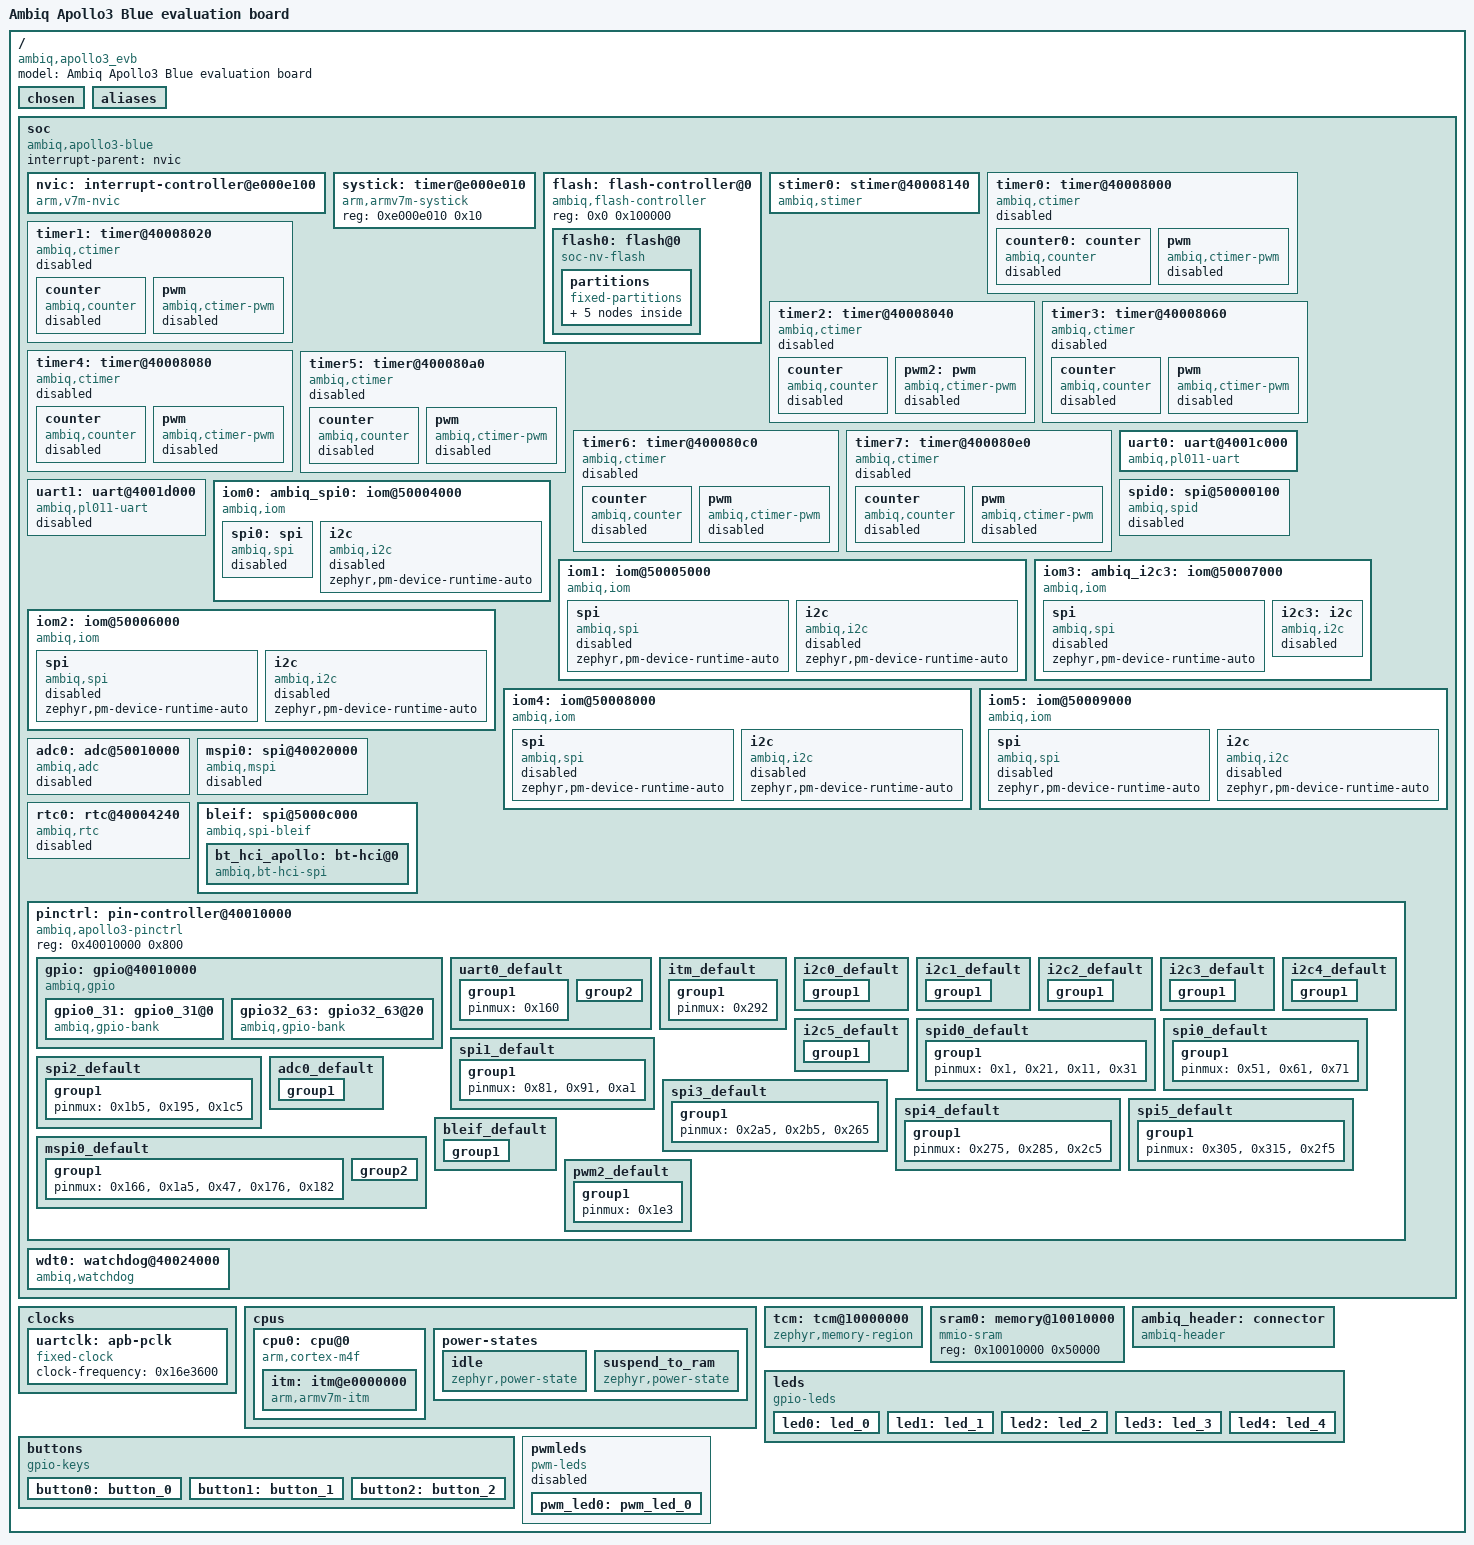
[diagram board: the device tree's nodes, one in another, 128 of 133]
/dts-v1/;

/* node '/' defined in zephyr/dts/common/skeleton.dtsi:9 */
/ {
	#address-cells = < 0x1 >;                      /* in zephyr/dts/common/skeleton.dtsi:10 */
	#size-cells = < 0x1 >;                         /* in zephyr/dts/common/skeleton.dtsi:11 */
	model = "Ambiq Apollo3 Blue evaluation board"; /* in zephyr/boards/ambiq/apollo3_evb/apollo3_evb.dts:8 */
	compatible = "ambiq,apollo3_evb";              /* in zephyr/boards/ambiq/apollo3_evb/apollo3_evb.dts:9 */

	/* node '/chosen' defined in zephyr/dts/common/skeleton.dtsi:13 */
	chosen {
		zephyr,itcm = &tcm;                       /* in zephyr/boards/ambiq/apollo3_evb/apollo3_evb.dts:12 */
		zephyr,sram = &sram0;                     /* in zephyr/boards/ambiq/apollo3_evb/apollo3_evb.dts:13 */
		zephyr,flash = &flash0;                   /* in zephyr/boards/ambiq/apollo3_evb/apollo3_evb.dts:14 */
		zephyr,console = &uart0;                  /* in zephyr/boards/ambiq/apollo3_evb/apollo3_evb.dts:15 */
		zephyr,shell-uart = &uart0;               /* in zephyr/boards/ambiq/apollo3_evb/apollo3_evb.dts:16 */
		zephyr,uart-mcumgr = &uart0;              /* in zephyr/boards/ambiq/apollo3_evb/apollo3_evb.dts:17 */
		zephyr,uart-pipe = &uart0;                /* in zephyr/boards/ambiq/apollo3_evb/apollo3_evb.dts:18 */
		zephyr,flash-controller = &flash;         /* in zephyr/boards/ambiq/apollo3_evb/apollo3_evb.dts:19 */
		zephyr,bt_hci = &bt_hci_apollo;           /* in zephyr/boards/ambiq/apollo3_evb/apollo3_evb.dts:20 */
		zephyr,code-partition = &slot0_partition; /* in zephyr/boards/ambiq/apollo3_evb/apollo3_evb.dts:21 */
	};

	/* node '/aliases' defined in zephyr/dts/common/skeleton.dtsi:15 */
	aliases {
		watchdog0 = &wdt0;    /* in zephyr/boards/ambiq/apollo3_evb/apollo3_evb.dts:25 */
		led0 = &led0;         /* in zephyr/boards/ambiq/apollo3_evb/apollo3_evb.dts:26 */
		led1 = &led1;         /* in zephyr/boards/ambiq/apollo3_evb/apollo3_evb.dts:27 */
		led2 = &led2;         /* in zephyr/boards/ambiq/apollo3_evb/apollo3_evb.dts:28 */
		sw0 = &button0;       /* in zephyr/boards/ambiq/apollo3_evb/apollo3_evb.dts:29 */
		sw1 = &button1;       /* in zephyr/boards/ambiq/apollo3_evb/apollo3_evb.dts:30 */
		mcuboot-led0 = &led0; /* in zephyr/boards/ambiq/apollo3_evb/apollo3_evb.dts:31 */
		pwm-led0 = &pwm_led0; /* in zephyr/boards/ambiq/apollo3_evb/apollo3_evb.dts:32 */
	};

	/* node '/soc' defined in zephyr/dts/arm/armv7-m.dtsi:6 */
	soc {
		#address-cells = < 0x1 >;          /* in zephyr/dts/arm/armv7-m.dtsi:7 */
		#size-cells = < 0x1 >;             /* in zephyr/dts/arm/armv7-m.dtsi:8 */
		interrupt-parent = < &nvic >;      /* in zephyr/dts/arm/armv7-m.dtsi:10 */
		ranges;                            /* in zephyr/dts/arm/armv7-m.dtsi:11 */
		compatible = "ambiq,apollo3-blue",
		             "ambiq,apollo3x",
		             "simple-bus";         /* in zephyr/dts/arm/ambiq/ambiq_apollo3_blue.dtsi:78 */

		/* node '/soc/interrupt-controller@e000e100' defined in zephyr/dts/arm/armv7-m.dtsi:13 */
		nvic: interrupt-controller@e000e100 {
			#address-cells = < 0x1 >;            /* in zephyr/dts/arm/armv7-m.dtsi:14 */
			compatible = "arm,v7m-nvic";         /* in zephyr/dts/arm/armv7-m.dtsi:15 */
			reg = < 0xe000e100 0xc00 >;          /* in zephyr/dts/arm/armv7-m.dtsi:16 */
			interrupt-controller;                /* in zephyr/dts/arm/armv7-m.dtsi:17 */
			#interrupt-cells = < 0x2 >;          /* in zephyr/dts/arm/armv7-m.dtsi:18 */
			arm,num-irq-priority-bits = < 0x3 >; /* in zephyr/dts/arm/ambiq/ambiq_apollo3_blue.dtsi:508 */
			phandle = < 0x1 >;                   /* in zephyr/dts/arm/armv7-m.dtsi:10 */
		};

		/* node '/soc/timer@e000e010' defined in zephyr/dts/arm/armv7-m.dtsi:21 */
		systick: timer@e000e010 {
			compatible = "arm,armv7m-systick"; /* in zephyr/dts/arm/armv7-m.dtsi:22 */
			reg = < 0xe000e010 0x10 >;         /* in zephyr/dts/arm/armv7-m.dtsi:23 */
		};

		/* node '/soc/flash-controller@0' defined in zephyr/dts/arm/ambiq/ambiq_apollo3_blue.dtsi:80 */
		flash: flash-controller@0 {
			compatible = "ambiq,flash-controller"; /* in zephyr/dts/arm/ambiq/ambiq_apollo3_blue.dtsi:81 */
			reg = < 0x0 0x100000 >;                /* in zephyr/dts/arm/ambiq/ambiq_apollo3_blue.dtsi:82 */
			#address-cells = < 0x1 >;              /* in zephyr/dts/arm/ambiq/ambiq_apollo3_blue.dtsi:84 */
			#size-cells = < 0x1 >;                 /* in zephyr/dts/arm/ambiq/ambiq_apollo3_blue.dtsi:85 */

			/* node '/soc/flash-controller@0/flash@0' defined in zephyr/dts/arm/ambiq/ambiq_apollo3_blue.dtsi:88 */
			flash0: flash@0 {
				compatible = "soc-nv-flash";   /* in zephyr/dts/arm/ambiq/ambiq_apollo3_blue.dtsi:89 */
				reg = < 0x0 0x100000 >;        /* in zephyr/dts/arm/ambiq/ambiq_apollo3_blue.dtsi:90 */
				erase-block-size = < 0x2000 >; /* in zephyr/boards/ambiq/apollo3_evb/apollo3_evb.dts:98 */
				write-block-size = < 0x4 >;    /* in zephyr/boards/ambiq/apollo3_evb/apollo3_evb.dts:99 */

				/* node '/soc/flash-controller@0/flash@0/partitions' defined in zephyr/boards/ambiq/apollo3_evb/apollo3_evb.dts:101 */
				partitions {
					compatible = "fixed-partitions"; /* in zephyr/boards/ambiq/apollo3_evb/apollo3_evb.dts:102 */
					#address-cells = < 0x1 >;        /* in zephyr/boards/ambiq/apollo3_evb/apollo3_evb.dts:103 */
					#size-cells = < 0x1 >;           /* in zephyr/boards/ambiq/apollo3_evb/apollo3_evb.dts:104 */

					/* node '/soc/flash-controller@0/flash@0/partitions/partition@0' defined in zephyr/boards/ambiq/apollo3_evb/apollo3_evb.dts:106 */
					internal_boot_partition: partition@0 {
						label = "internal_bootloader"; /* in zephyr/boards/ambiq/apollo3_evb/apollo3_evb.dts:107 */
						reg = < 0x0 0xc000 >;          /* in zephyr/boards/ambiq/apollo3_evb/apollo3_evb.dts:108 */
					};

					/* node '/soc/flash-controller@0/flash@0/partitions/partition@c000' defined in zephyr/boards/ambiq/apollo3_evb/apollo3_evb.dts:111 */
					boot_partition: partition@c000 {
						label = "mcuboot";       /* in zephyr/boards/ambiq/apollo3_evb/apollo3_evb.dts:112 */
						reg = < 0xc000 0xc000 >; /* in zephyr/boards/ambiq/apollo3_evb/apollo3_evb.dts:113 */
					};

					/* node '/soc/flash-controller@0/flash@0/partitions/partition@18000' defined in zephyr/boards/ambiq/apollo3_evb/apollo3_evb.dts:116 */
					slot0_partition: partition@18000 {
						label = "image-0";         /* in zephyr/boards/ambiq/apollo3_evb/apollo3_evb.dts:117 */
						reg = < 0x18000 0x72000 >; /* in zephyr/boards/ambiq/apollo3_evb/apollo3_evb.dts:118 */
					};

					/* node '/soc/flash-controller@0/flash@0/partitions/partition@8a000' defined in zephyr/boards/ambiq/apollo3_evb/apollo3_evb.dts:121 */
					slot1_partition: partition@8a000 {
						label = "image-1";         /* in zephyr/boards/ambiq/apollo3_evb/apollo3_evb.dts:122 */
						reg = < 0x8a000 0x72000 >; /* in zephyr/boards/ambiq/apollo3_evb/apollo3_evb.dts:123 */
					};

					/* node '/soc/flash-controller@0/flash@0/partitions/partition@fc000' defined in zephyr/boards/ambiq/apollo3_evb/apollo3_evb.dts:127 */
					storage_partition: partition@fc000 {
						label = "storage";        /* in zephyr/boards/ambiq/apollo3_evb/apollo3_evb.dts:128 */
						reg = < 0xfc000 0x4000 >; /* in zephyr/boards/ambiq/apollo3_evb/apollo3_evb.dts:129 */
					};
				};
			};
		};

		/* node '/soc/stimer@40008140' defined in zephyr/dts/arm/ambiq/ambiq_apollo3_blue.dtsi:94 */
		stimer0: stimer@40008140 {
			compatible = "ambiq,stimer"; /* in zephyr/dts/arm/ambiq/ambiq_apollo3_blue.dtsi:95 */
			reg = < 0x40008140 0x80 >;   /* in zephyr/dts/arm/ambiq/ambiq_apollo3_blue.dtsi:96 */
			interrupts = < 0x17 0x0 >;   /* in zephyr/dts/arm/ambiq/ambiq_apollo3_blue.dtsi:97 */
			status = "okay";             /* in zephyr/dts/arm/ambiq/ambiq_apollo3_blue.dtsi:98 */
			clk-source = < 0x3 >;        /* in zephyr/boards/ambiq/apollo3_evb/apollo3_evb.dts:135 */
		};

		/* node '/soc/timer@40008000' defined in zephyr/dts/arm/ambiq/ambiq_apollo3_blue.dtsi:101 */
		timer0: timer@40008000 {
			compatible = "ambiq,ctimer";         /* in zephyr/dts/arm/ambiq/ambiq_apollo3_blue.dtsi:102 */
			reg = < 0x40008000 0x20 >;           /* in zephyr/dts/arm/ambiq/ambiq_apollo3_blue.dtsi:103 */
			interrupts = < 0xe 0x0 >;            /* in zephyr/dts/arm/ambiq/ambiq_apollo3_blue.dtsi:104 */
			clk-source = "CLK_SELECT_HFRC_3MHZ"; /* in zephyr/dts/arm/ambiq/ambiq_apollo3_blue.dtsi:105 */
			status = "disabled";                 /* in zephyr/dts/arm/ambiq/ambiq_apollo3_blue.dtsi:106 */

			/* node '/soc/timer@40008000/counter' defined in zephyr/dts/arm/ambiq/ambiq_apollo3_blue.dtsi:108 */
			counter0: counter {
				compatible = "ambiq,counter"; /* in zephyr/dts/arm/ambiq/ambiq_apollo3_blue.dtsi:109 */
				status = "disabled";          /* in zephyr/boards/ambiq/apollo3_evb/apollo3_evb.dts:184 */
			};

			/* node '/soc/timer@40008000/pwm' defined in zephyr/dts/arm/ambiq/ambiq_apollo3_blue.dtsi:113 */
			pwm {
				compatible = "ambiq,ctimer-pwm"; /* in zephyr/dts/arm/ambiq/ambiq_apollo3_blue.dtsi:114 */
				status = "disabled";             /* in zephyr/dts/arm/ambiq/ambiq_apollo3_blue.dtsi:115 */
				#pwm-cells = < 0x3 >;            /* in zephyr/dts/arm/ambiq/ambiq_apollo3_blue.dtsi:116 */
			};
		};

		/* node '/soc/timer@40008020' defined in zephyr/dts/arm/ambiq/ambiq_apollo3_blue.dtsi:120 */
		timer1: timer@40008020 {
			compatible = "ambiq,ctimer";         /* in zephyr/dts/arm/ambiq/ambiq_apollo3_blue.dtsi:121 */
			reg = < 0x40008020 0x20 >;           /* in zephyr/dts/arm/ambiq/ambiq_apollo3_blue.dtsi:122 */
			interrupts = < 0xe 0x0 >;            /* in zephyr/dts/arm/ambiq/ambiq_apollo3_blue.dtsi:123 */
			clk-source = "CLK_SELECT_HFRC_3MHZ"; /* in zephyr/dts/arm/ambiq/ambiq_apollo3_blue.dtsi:124 */
			status = "disabled";                 /* in zephyr/dts/arm/ambiq/ambiq_apollo3_blue.dtsi:125 */

			/* node '/soc/timer@40008020/counter' defined in zephyr/dts/arm/ambiq/ambiq_apollo3_blue.dtsi:127 */
			counter {
				compatible = "ambiq,counter"; /* in zephyr/dts/arm/ambiq/ambiq_apollo3_blue.dtsi:128 */
				status = "disabled";          /* in zephyr/dts/arm/ambiq/ambiq_apollo3_blue.dtsi:129 */
			};

			/* node '/soc/timer@40008020/pwm' defined in zephyr/dts/arm/ambiq/ambiq_apollo3_blue.dtsi:132 */
			pwm {
				compatible = "ambiq,ctimer-pwm"; /* in zephyr/dts/arm/ambiq/ambiq_apollo3_blue.dtsi:133 */
				status = "disabled";             /* in zephyr/dts/arm/ambiq/ambiq_apollo3_blue.dtsi:134 */
				#pwm-cells = < 0x3 >;            /* in zephyr/dts/arm/ambiq/ambiq_apollo3_blue.dtsi:135 */
			};
		};

		/* node '/soc/timer@40008040' defined in zephyr/dts/arm/ambiq/ambiq_apollo3_blue.dtsi:139 */
		timer2: timer@40008040 {
			compatible = "ambiq,ctimer";             /* in zephyr/dts/arm/ambiq/ambiq_apollo3_blue.dtsi:140 */
			reg = < 0x40008040 0x20 >;               /* in zephyr/dts/arm/ambiq/ambiq_apollo3_blue.dtsi:141 */
			interrupts = < 0xe 0x0 >;                /* in zephyr/dts/arm/ambiq/ambiq_apollo3_blue.dtsi:142 */
			clk-source = "CLK_SELECT_HFRC_187_5KHZ"; /* in zephyr/dts/arm/ambiq/ambiq_apollo3_blue.dtsi:143 */
			status = "disabled";                     /* in zephyr/dts/arm/ambiq/ambiq_apollo3_blue.dtsi:144 */

			/* node '/soc/timer@40008040/counter' defined in zephyr/dts/arm/ambiq/ambiq_apollo3_blue.dtsi:146 */
			counter {
				compatible = "ambiq,counter"; /* in zephyr/dts/arm/ambiq/ambiq_apollo3_blue.dtsi:147 */
				status = "disabled";          /* in zephyr/dts/arm/ambiq/ambiq_apollo3_blue.dtsi:148 */
			};

			/* node '/soc/timer@40008040/pwm' defined in zephyr/dts/arm/ambiq/ambiq_apollo3_blue.dtsi:151 */
			pwm2: pwm {
				compatible = "ambiq,ctimer-pwm"; /* in zephyr/dts/arm/ambiq/ambiq_apollo3_blue.dtsi:152 */
				#pwm-cells = < 0x3 >;            /* in zephyr/dts/arm/ambiq/ambiq_apollo3_blue.dtsi:154 */
				timer-segment = "SEGMENT_B";     /* in zephyr/boards/ambiq/apollo3_evb/apollo3_evb.dts:190 */
				pwm-type = "PWM_REPEAT";         /* in zephyr/boards/ambiq/apollo3_evb/apollo3_evb.dts:191 */
				pinctrl-0 = < &pwm2_default >;   /* in zephyr/boards/ambiq/apollo3_evb/apollo3_evb.dts:192 */
				pinctrl-names = "default";       /* in zephyr/boards/ambiq/apollo3_evb/apollo3_evb.dts:193 */
				status = "disabled";             /* in zephyr/boards/ambiq/apollo3_evb/apollo3_evb.dts:194 */
				phandle = < 0xe >;               /* in zephyr/boards/ambiq/apollo3_evb/apollo3_evb.dts:91 */
			};
		};

		/* node '/soc/timer@40008060' defined in zephyr/dts/arm/ambiq/ambiq_apollo3_blue.dtsi:158 */
		timer3: timer@40008060 {
			compatible = "ambiq,ctimer";         /* in zephyr/dts/arm/ambiq/ambiq_apollo3_blue.dtsi:159 */
			reg = < 0x40008060 0x20 >;           /* in zephyr/dts/arm/ambiq/ambiq_apollo3_blue.dtsi:160 */
			interrupts = < 0xe 0x0 >;            /* in zephyr/dts/arm/ambiq/ambiq_apollo3_blue.dtsi:161 */
			clk-source = "CLK_SELECT_HFRC_3MHZ"; /* in zephyr/dts/arm/ambiq/ambiq_apollo3_blue.dtsi:162 */
			status = "disabled";                 /* in zephyr/dts/arm/ambiq/ambiq_apollo3_blue.dtsi:163 */

			/* node '/soc/timer@40008060/counter' defined in zephyr/dts/arm/ambiq/ambiq_apollo3_blue.dtsi:165 */
			counter {
				compatible = "ambiq,counter"; /* in zephyr/dts/arm/ambiq/ambiq_apollo3_blue.dtsi:166 */
				status = "disabled";          /* in zephyr/dts/arm/ambiq/ambiq_apollo3_blue.dtsi:167 */
			};

			/* node '/soc/timer@40008060/pwm' defined in zephyr/dts/arm/ambiq/ambiq_apollo3_blue.dtsi:170 */
			pwm {
				compatible = "ambiq,ctimer-pwm"; /* in zephyr/dts/arm/ambiq/ambiq_apollo3_blue.dtsi:171 */
				status = "disabled";             /* in zephyr/dts/arm/ambiq/ambiq_apollo3_blue.dtsi:172 */
				#pwm-cells = < 0x3 >;            /* in zephyr/dts/arm/ambiq/ambiq_apollo3_blue.dtsi:173 */
			};
		};

		/* node '/soc/timer@40008080' defined in zephyr/dts/arm/ambiq/ambiq_apollo3_blue.dtsi:177 */
		timer4: timer@40008080 {
			compatible = "ambiq,ctimer";         /* in zephyr/dts/arm/ambiq/ambiq_apollo3_blue.dtsi:178 */
			reg = < 0x40008080 0x20 >;           /* in zephyr/dts/arm/ambiq/ambiq_apollo3_blue.dtsi:179 */
			interrupts = < 0xe 0x0 >;            /* in zephyr/dts/arm/ambiq/ambiq_apollo3_blue.dtsi:180 */
			clk-source = "CLK_SELECT_HFRC_3MHZ"; /* in zephyr/dts/arm/ambiq/ambiq_apollo3_blue.dtsi:181 */
			status = "disabled";                 /* in zephyr/dts/arm/ambiq/ambiq_apollo3_blue.dtsi:182 */

			/* node '/soc/timer@40008080/counter' defined in zephyr/dts/arm/ambiq/ambiq_apollo3_blue.dtsi:184 */
			counter {
				compatible = "ambiq,counter"; /* in zephyr/dts/arm/ambiq/ambiq_apollo3_blue.dtsi:185 */
				status = "disabled";          /* in zephyr/dts/arm/ambiq/ambiq_apollo3_blue.dtsi:186 */
			};

			/* node '/soc/timer@40008080/pwm' defined in zephyr/dts/arm/ambiq/ambiq_apollo3_blue.dtsi:189 */
			pwm {
				compatible = "ambiq,ctimer-pwm"; /* in zephyr/dts/arm/ambiq/ambiq_apollo3_blue.dtsi:190 */
				status = "disabled";             /* in zephyr/dts/arm/ambiq/ambiq_apollo3_blue.dtsi:191 */
				#pwm-cells = < 0x3 >;            /* in zephyr/dts/arm/ambiq/ambiq_apollo3_blue.dtsi:192 */
			};
		};

		/* node '/soc/timer@400080a0' defined in zephyr/dts/arm/ambiq/ambiq_apollo3_blue.dtsi:196 */
		timer5: timer@400080a0 {
			compatible = "ambiq,ctimer";         /* in zephyr/dts/arm/ambiq/ambiq_apollo3_blue.dtsi:197 */
			reg = < 0x400080a0 0x20 >;           /* in zephyr/dts/arm/ambiq/ambiq_apollo3_blue.dtsi:198 */
			interrupts = < 0xe 0x0 >;            /* in zephyr/dts/arm/ambiq/ambiq_apollo3_blue.dtsi:199 */
			clk-source = "CLK_SELECT_HFRC_3MHZ"; /* in zephyr/dts/arm/ambiq/ambiq_apollo3_blue.dtsi:200 */
			status = "disabled";                 /* in zephyr/dts/arm/ambiq/ambiq_apollo3_blue.dtsi:201 */

			/* node '/soc/timer@400080a0/counter' defined in zephyr/dts/arm/ambiq/ambiq_apollo3_blue.dtsi:203 */
			counter {
				compatible = "ambiq,counter"; /* in zephyr/dts/arm/ambiq/ambiq_apollo3_blue.dtsi:204 */
				status = "disabled";          /* in zephyr/dts/arm/ambiq/ambiq_apollo3_blue.dtsi:205 */
			};

			/* node '/soc/timer@400080a0/pwm' defined in zephyr/dts/arm/ambiq/ambiq_apollo3_blue.dtsi:208 */
			pwm {
				compatible = "ambiq,ctimer-pwm"; /* in zephyr/dts/arm/ambiq/ambiq_apollo3_blue.dtsi:209 */
				status = "disabled";             /* in zephyr/dts/arm/ambiq/ambiq_apollo3_blue.dtsi:210 */
				#pwm-cells = < 0x3 >;            /* in zephyr/dts/arm/ambiq/ambiq_apollo3_blue.dtsi:211 */
			};
		};

		/* node '/soc/timer@400080c0' defined in zephyr/dts/arm/ambiq/ambiq_apollo3_blue.dtsi:215 */
		timer6: timer@400080c0 {
			compatible = "ambiq,ctimer";         /* in zephyr/dts/arm/ambiq/ambiq_apollo3_blue.dtsi:216 */
			reg = < 0x400080c0 0x20 >;           /* in zephyr/dts/arm/ambiq/ambiq_apollo3_blue.dtsi:217 */
			interrupts = < 0xe 0x0 >;            /* in zephyr/dts/arm/ambiq/ambiq_apollo3_blue.dtsi:218 */
			clk-source = "CLK_SELECT_HFRC_3MHZ"; /* in zephyr/dts/arm/ambiq/ambiq_apollo3_blue.dtsi:219 */
			status = "disabled";                 /* in zephyr/dts/arm/ambiq/ambiq_apollo3_blue.dtsi:220 */

			/* node '/soc/timer@400080c0/counter' defined in zephyr/dts/arm/ambiq/ambiq_apollo3_blue.dtsi:222 */
			counter {
				compatible = "ambiq,counter"; /* in zephyr/dts/arm/ambiq/ambiq_apollo3_blue.dtsi:223 */
				status = "disabled";          /* in zephyr/dts/arm/ambiq/ambiq_apollo3_blue.dtsi:224 */
			};

			/* node '/soc/timer@400080c0/pwm' defined in zephyr/dts/arm/ambiq/ambiq_apollo3_blue.dtsi:227 */
			pwm {
				compatible = "ambiq,ctimer-pwm"; /* in zephyr/dts/arm/ambiq/ambiq_apollo3_blue.dtsi:228 */
				status = "disabled";             /* in zephyr/dts/arm/ambiq/ambiq_apollo3_blue.dtsi:229 */
				#pwm-cells = < 0x3 >;            /* in zephyr/dts/arm/ambiq/ambiq_apollo3_blue.dtsi:230 */
			};
		};

		/* node '/soc/timer@400080e0' defined in zephyr/dts/arm/ambiq/ambiq_apollo3_blue.dtsi:234 */
		timer7: timer@400080e0 {
			compatible = "ambiq,ctimer";         /* in zephyr/dts/arm/ambiq/ambiq_apollo3_blue.dtsi:235 */
			reg = < 0x400080e0 0x20 >;           /* in zephyr/dts/arm/ambiq/ambiq_apollo3_blue.dtsi:236 */
			interrupts = < 0xe 0x0 >;            /* in zephyr/dts/arm/ambiq/ambiq_apollo3_blue.dtsi:237 */
			clk-source = "CLK_SELECT_HFRC_3MHZ"; /* in zephyr/dts/arm/ambiq/ambiq_apollo3_blue.dtsi:238 */
			status = "disabled";                 /* in zephyr/dts/arm/ambiq/ambiq_apollo3_blue.dtsi:239 */

			/* node '/soc/timer@400080e0/counter' defined in zephyr/dts/arm/ambiq/ambiq_apollo3_blue.dtsi:241 */
			counter {
				compatible = "ambiq,counter"; /* in zephyr/dts/arm/ambiq/ambiq_apollo3_blue.dtsi:242 */
				status = "disabled";          /* in zephyr/dts/arm/ambiq/ambiq_apollo3_blue.dtsi:243 */
			};

			/* node '/soc/timer@400080e0/pwm' defined in zephyr/dts/arm/ambiq/ambiq_apollo3_blue.dtsi:246 */
			pwm {
				compatible = "ambiq,ctimer-pwm"; /* in zephyr/dts/arm/ambiq/ambiq_apollo3_blue.dtsi:247 */
				status = "disabled";             /* in zephyr/dts/arm/ambiq/ambiq_apollo3_blue.dtsi:248 */
				#pwm-cells = < 0x3 >;            /* in zephyr/dts/arm/ambiq/ambiq_apollo3_blue.dtsi:249 */
			};
		};

		/* node '/soc/uart@4001c000' defined in zephyr/dts/arm/ambiq/ambiq_apollo3_blue.dtsi:253 */
		uart0: uart@4001c000 {
			compatible = "ambiq,pl011-uart",
			             "arm,pl011";        /* in zephyr/dts/arm/ambiq/ambiq_apollo3_blue.dtsi:254 */
			reg = < 0x4001c000 0x1000 >;     /* in zephyr/dts/arm/ambiq/ambiq_apollo3_blue.dtsi:255 */
			interrupts = < 0xf 0x0 >;        /* in zephyr/dts/arm/ambiq/ambiq_apollo3_blue.dtsi:256 */
			interrupt-names = "UART0";       /* in zephyr/dts/arm/ambiq/ambiq_apollo3_blue.dtsi:257 */
			clocks = < &uartclk >;           /* in zephyr/dts/arm/ambiq/ambiq_apollo3_blue.dtsi:259 */
			zephyr,pm-device-runtime-auto;   /* in zephyr/dts/arm/ambiq/ambiq_apollo3_blue.dtsi:260 */
			current-speed = < 0x1c200 >;     /* in zephyr/boards/ambiq/apollo3_evb/apollo3_evb.dts:145 */
			pinctrl-0 = < &uart0_default >;  /* in zephyr/boards/ambiq/apollo3_evb/apollo3_evb.dts:146 */
			pinctrl-names = "default";       /* in zephyr/boards/ambiq/apollo3_evb/apollo3_evb.dts:147 */
			status = "okay";                 /* in zephyr/boards/ambiq/apollo3_evb/apollo3_evb.dts:148 */
		};

		/* node '/soc/uart@4001d000' defined in zephyr/dts/arm/ambiq/ambiq_apollo3_blue.dtsi:263 */
		uart1: uart@4001d000 {
			compatible = "ambiq,pl011-uart",
			             "arm,pl011";        /* in zephyr/dts/arm/ambiq/ambiq_apollo3_blue.dtsi:264 */
			reg = < 0x4001d000 0x1000 >;     /* in zephyr/dts/arm/ambiq/ambiq_apollo3_blue.dtsi:265 */
			interrupts = < 0x10 0x0 >;       /* in zephyr/dts/arm/ambiq/ambiq_apollo3_blue.dtsi:266 */
			interrupt-names = "UART1";       /* in zephyr/dts/arm/ambiq/ambiq_apollo3_blue.dtsi:267 */
			status = "disabled";             /* in zephyr/dts/arm/ambiq/ambiq_apollo3_blue.dtsi:268 */
			clocks = < &uartclk >;           /* in zephyr/dts/arm/ambiq/ambiq_apollo3_blue.dtsi:269 */
			zephyr,pm-device-runtime-auto;   /* in zephyr/dts/arm/ambiq/ambiq_apollo3_blue.dtsi:270 */
		};

		/* node '/soc/spi@50000100' defined in zephyr/dts/arm/ambiq/ambiq_apollo3_blue.dtsi:273 */
		spid0: spi@50000100 {
			compatible = "ambiq,spid";     /* in zephyr/dts/arm/ambiq/ambiq_apollo3_blue.dtsi:274 */
			reg = < 0x50000100 0x1000 >;   /* in zephyr/dts/arm/ambiq/ambiq_apollo3_blue.dtsi:275 */
			#address-cells = < 0x1 >;      /* in zephyr/dts/arm/ambiq/ambiq_apollo3_blue.dtsi:276 */
			#size-cells = < 0x0 >;         /* in zephyr/dts/arm/ambiq/ambiq_apollo3_blue.dtsi:277 */
			interrupts = < 0x4 0x0 >;      /* in zephyr/dts/arm/ambiq/ambiq_apollo3_blue.dtsi:278 */
			status = "disabled";           /* in zephyr/dts/arm/ambiq/ambiq_apollo3_blue.dtsi:279 */
			zephyr,pm-device-runtime-auto; /* in zephyr/dts/arm/ambiq/ambiq_apollo3_blue.dtsi:280 */
		};

		/* node '/soc/iom@50004000' defined in zephyr/dts/arm/ambiq/ambiq_apollo3_blue.dtsi:283 */
		iom0: ambiq_spi0: iom@50004000 {
			compatible = "ambiq,iom";    /* in zephyr/dts/arm/ambiq/ambiq_apollo3_blue.dtsi:284 */
			reg = < 0x50004000 0x1000 >; /* in zephyr/dts/arm/ambiq/ambiq_apollo3_blue.dtsi:285 */
			interrupts = < 0x6 0x0 >;    /* in zephyr/dts/arm/ambiq/ambiq_apollo3_blue.dtsi:286 */

			/* node '/soc/iom@50004000/spi' defined in zephyr/dts/arm/ambiq/ambiq_apollo3_blue.dtsi:288 */
			spi0: spi {
				compatible = "ambiq,spi";         /* in zephyr/dts/arm/ambiq/ambiq_apollo3_blue.dtsi:289 */
				#address-cells = < 0x1 >;         /* in zephyr/dts/arm/ambiq/ambiq_apollo3_blue.dtsi:290 */
				#size-cells = < 0x0 >;            /* in zephyr/dts/arm/ambiq/ambiq_apollo3_blue.dtsi:291 */
				zephyr,pm-device-runtime-auto;    /* in zephyr/dts/arm/ambiq/ambiq_apollo3_blue.dtsi:293 */
				pinctrl-0 = < &spi0_default >;    /* in zephyr/boards/ambiq/apollo3_evb/apollo3_evb.dts:163 */
				pinctrl-names = "default";        /* in zephyr/boards/ambiq/apollo3_evb/apollo3_evb.dts:164 */
				cs-gpios = < &gpio0_31 0xb 0x1 >; /* in zephyr/boards/ambiq/apollo3_evb/apollo3_evb.dts:165 */
				clock-frequency = < 0xf4240 >;    /* in zephyr/boards/ambiq/apollo3_evb/apollo3_evb.dts:166 */
				status = "disabled";              /* in zephyr/boards/ambiq/apollo3_evb/apollo3_evb.dts:167 */
			};

			/* node '/soc/iom@50004000/i2c' defined in zephyr/dts/arm/ambiq/ambiq_apollo3_blue.dtsi:296 */
			i2c {
				compatible = "ambiq,i2c";      /* in zephyr/dts/arm/ambiq/ambiq_apollo3_blue.dtsi:297 */
				#address-cells = < 0x1 >;      /* in zephyr/dts/arm/ambiq/ambiq_apollo3_blue.dtsi:298 */
				#size-cells = < 0x0 >;         /* in zephyr/dts/arm/ambiq/ambiq_apollo3_blue.dtsi:299 */
				status = "disabled";           /* in zephyr/dts/arm/ambiq/ambiq_apollo3_blue.dtsi:300 */
				zephyr,pm-device-runtime-auto; /* in zephyr/dts/arm/ambiq/ambiq_apollo3_blue.dtsi:301 */
			};
		};

		/* node '/soc/iom@50005000' defined in zephyr/dts/arm/ambiq/ambiq_apollo3_blue.dtsi:305 */
		iom1: iom@50005000 {
			compatible = "ambiq,iom";    /* in zephyr/dts/arm/ambiq/ambiq_apollo3_blue.dtsi:306 */
			reg = < 0x50005000 0x1000 >; /* in zephyr/dts/arm/ambiq/ambiq_apollo3_blue.dtsi:307 */
			interrupts = < 0x7 0x0 >;    /* in zephyr/dts/arm/ambiq/ambiq_apollo3_blue.dtsi:308 */

			/* node '/soc/iom@50005000/spi' defined in zephyr/dts/arm/ambiq/ambiq_apollo3_blue.dtsi:310 */
			spi {
				compatible = "ambiq,spi";      /* in zephyr/dts/arm/ambiq/ambiq_apollo3_blue.dtsi:311 */
				#address-cells = < 0x1 >;      /* in zephyr/dts/arm/ambiq/ambiq_apollo3_blue.dtsi:312 */
				#size-cells = < 0x0 >;         /* in zephyr/dts/arm/ambiq/ambiq_apollo3_blue.dtsi:313 */
				status = "disabled";           /* in zephyr/dts/arm/ambiq/ambiq_apollo3_blue.dtsi:314 */
				zephyr,pm-device-runtime-auto; /* in zephyr/dts/arm/ambiq/ambiq_apollo3_blue.dtsi:315 */
			};

			/* node '/soc/iom@50005000/i2c' defined in zephyr/dts/arm/ambiq/ambiq_apollo3_blue.dtsi:318 */
			i2c {
				compatible = "ambiq,i2c";      /* in zephyr/dts/arm/ambiq/ambiq_apollo3_blue.dtsi:319 */
				#address-cells = < 0x1 >;      /* in zephyr/dts/arm/ambiq/ambiq_apollo3_blue.dtsi:320 */
				#size-cells = < 0x0 >;         /* in zephyr/dts/arm/ambiq/ambiq_apollo3_blue.dtsi:321 */
				status = "disabled";           /* in zephyr/dts/arm/ambiq/ambiq_apollo3_blue.dtsi:322 */
				zephyr,pm-device-runtime-auto; /* in zephyr/dts/arm/ambiq/ambiq_apollo3_blue.dtsi:323 */
			};
		};

		/* node '/soc/iom@50006000' defined in zephyr/dts/arm/ambiq/ambiq_apollo3_blue.dtsi:327 */
		iom2: iom@50006000 {
			compatible = "ambiq,iom";    /* in zephyr/dts/arm/ambiq/ambiq_apollo3_blue.dtsi:328 */
			reg = < 0x50006000 0x1000 >; /* in zephyr/dts/arm/ambiq/ambiq_apollo3_blue.dtsi:329 */
			interrupts = < 0x8 0x0 >;    /* in zephyr/dts/arm/ambiq/ambiq_apollo3_blue.dtsi:330 */

			/* node '/soc/iom@50006000/spi' defined in zephyr/dts/arm/ambiq/ambiq_apollo3_blue.dtsi:332 */
			spi {
				compatible = "ambiq,spi";      /* in zephyr/dts/arm/ambiq/ambiq_apollo3_blue.dtsi:333 */
				#address-cells = < 0x1 >;      /* in zephyr/dts/arm/ambiq/ambiq_apollo3_blue.dtsi:334 */
				#size-cells = < 0x0 >;         /* in zephyr/dts/arm/ambiq/ambiq_apollo3_blue.dtsi:335 */
				status = "disabled";           /* in zephyr/dts/arm/ambiq/ambiq_apollo3_blue.dtsi:336 */
				zephyr,pm-device-runtime-auto; /* in zephyr/dts/arm/ambiq/ambiq_apollo3_blue.dtsi:337 */
			};

			/* node '/soc/iom@50006000/i2c' defined in zephyr/dts/arm/ambiq/ambiq_apollo3_blue.dtsi:340 */
			i2c {
				compatible = "ambiq,i2c";      /* in zephyr/dts/arm/ambiq/ambiq_apollo3_blue.dtsi:341 */
				#address-cells = < 0x1 >;      /* in zephyr/dts/arm/ambiq/ambiq_apollo3_blue.dtsi:342 */
				#size-cells = < 0x0 >;         /* in zephyr/dts/arm/ambiq/ambiq_apollo3_blue.dtsi:343 */
				status = "disabled";           /* in zephyr/dts/arm/ambiq/ambiq_apollo3_blue.dtsi:344 */
				zephyr,pm-device-runtime-auto; /* in zephyr/dts/arm/ambiq/ambiq_apollo3_blue.dtsi:345 */
			};
		};

		/* node '/soc/iom@50007000' defined in zephyr/dts/arm/ambiq/ambiq_apollo3_blue.dtsi:349 */
		iom3: ambiq_i2c3: iom@50007000 {
			compatible = "ambiq,iom";    /* in zephyr/dts/arm/ambiq/ambiq_apollo3_blue.dtsi:350 */
			reg = < 0x50007000 0x1000 >; /* in zephyr/dts/arm/ambiq/ambiq_apollo3_blue.dtsi:351 */
			interrupts = < 0x9 0x0 >;    /* in zephyr/dts/arm/ambiq/ambiq_apollo3_blue.dtsi:352 */

			/* node '/soc/iom@50007000/spi' defined in zephyr/dts/arm/ambiq/ambiq_apollo3_blue.dtsi:354 */
			spi {
				compatible = "ambiq,spi";      /* in zephyr/dts/arm/ambiq/ambiq_apollo3_blue.dtsi:355 */
				#address-cells = < 0x1 >;      /* in zephyr/dts/arm/ambiq/ambiq_apollo3_blue.dtsi:356 */
				#size-cells = < 0x0 >;         /* in zephyr/dts/arm/ambiq/ambiq_apollo3_blue.dtsi:357 */
				status = "disabled";           /* in zephyr/dts/arm/ambiq/ambiq_apollo3_blue.dtsi:358 */
				zephyr,pm-device-runtime-auto; /* in zephyr/dts/arm/ambiq/ambiq_apollo3_blue.dtsi:359 */
			};

			/* node '/soc/iom@50007000/i2c' defined in zephyr/dts/arm/ambiq/ambiq_apollo3_blue.dtsi:362 */
			i2c3: i2c {
				compatible = "ambiq,i2c";            /* in zephyr/dts/arm/ambiq/ambiq_apollo3_blue.dtsi:363 */
				#address-cells = < 0x1 >;            /* in zephyr/dts/arm/ambiq/ambiq_apollo3_blue.dtsi:364 */
				#size-cells = < 0x0 >;               /* in zephyr/dts/arm/ambiq/ambiq_apollo3_blue.dtsi:365 */
				zephyr,pm-device-runtime-auto;       /* in zephyr/dts/arm/ambiq/ambiq_apollo3_blue.dtsi:367 */
				pinctrl-0 = < &i2c3_default >;       /* in zephyr/boards/ambiq/apollo3_evb/apollo3_evb.dts:173 */
				pinctrl-names = "default";           /* in zephyr/boards/ambiq/apollo3_evb/apollo3_evb.dts:174 */
				clock-frequency = < 0x186a0 >;       /* in zephyr/boards/ambiq/apollo3_evb/apollo3_evb.dts:175 */
				scl-gpios = < &gpio32_63 0xa 0x16 >; /* in zephyr/boards/ambiq/apollo3_evb/apollo3_evb.dts:176 */
				sda-gpios = < &gpio32_63 0xb 0x16 >; /* in zephyr/boards/ambiq/apollo3_evb/apollo3_evb.dts:177 */
				status = "disabled";                 /* in zephyr/boards/ambiq/apollo3_evb/apollo3_evb.dts:178 */
			};
		};

		/* node '/soc/iom@50008000' defined in zephyr/dts/arm/ambiq/ambiq_apollo3_blue.dtsi:371 */
		iom4: iom@50008000 {
			compatible = "ambiq,iom";    /* in zephyr/dts/arm/ambiq/ambiq_apollo3_blue.dtsi:372 */
			reg = < 0x50008000 0x1000 >; /* in zephyr/dts/arm/ambiq/ambiq_apollo3_blue.dtsi:373 */
			interrupts = < 0xa 0x0 >;    /* in zephyr/dts/arm/ambiq/ambiq_apollo3_blue.dtsi:374 */

			/* node '/soc/iom@50008000/spi' defined in zephyr/dts/arm/ambiq/ambiq_apollo3_blue.dtsi:376 */
			spi {
				compatible = "ambiq,spi";      /* in zephyr/dts/arm/ambiq/ambiq_apollo3_blue.dtsi:377 */
				#address-cells = < 0x1 >;      /* in zephyr/dts/arm/ambiq/ambiq_apollo3_blue.dtsi:378 */
				#size-cells = < 0x0 >;         /* in zephyr/dts/arm/ambiq/ambiq_apollo3_blue.dtsi:379 */
				status = "disabled";           /* in zephyr/dts/arm/ambiq/ambiq_apollo3_blue.dtsi:380 */
				zephyr,pm-device-runtime-auto; /* in zephyr/dts/arm/ambiq/ambiq_apollo3_blue.dtsi:381 */
			};

			/* node '/soc/iom@50008000/i2c' defined in zephyr/dts/arm/ambiq/ambiq_apollo3_blue.dtsi:384 */
			i2c {
				compatible = "ambiq,i2c";      /* in zephyr/dts/arm/ambiq/ambiq_apollo3_blue.dtsi:385 */
				#address-cells = < 0x1 >;      /* in zephyr/dts/arm/ambiq/ambiq_apollo3_blue.dtsi:386 */
				#size-cells = < 0x0 >;         /* in zephyr/dts/arm/ambiq/ambiq_apollo3_blue.dtsi:387 */
				status = "disabled";           /* in zephyr/dts/arm/ambiq/ambiq_apollo3_blue.dtsi:388 */
				zephyr,pm-device-runtime-auto; /* in zephyr/dts/arm/ambiq/ambiq_apollo3_blue.dtsi:389 */
			};
		};

		/* node '/soc/iom@50009000' defined in zephyr/dts/arm/ambiq/ambiq_apollo3_blue.dtsi:393 */
		iom5: iom@50009000 {
			compatible = "ambiq,iom";    /* in zephyr/dts/arm/ambiq/ambiq_apollo3_blue.dtsi:394 */
			reg = < 0x50009000 0x1000 >; /* in zephyr/dts/arm/ambiq/ambiq_apollo3_blue.dtsi:395 */
			interrupts = < 0xb 0x0 >;    /* in zephyr/dts/arm/ambiq/ambiq_apollo3_blue.dtsi:396 */

			/* node '/soc/iom@50009000/spi' defined in zephyr/dts/arm/ambiq/ambiq_apollo3_blue.dtsi:398 */
			spi {
				compatible = "ambiq,spi";      /* in zephyr/dts/arm/ambiq/ambiq_apollo3_blue.dtsi:399 */
				#address-cells = < 0x1 >;      /* in zephyr/dts/arm/ambiq/ambiq_apollo3_blue.dtsi:400 */
				#size-cells = < 0x0 >;         /* in zephyr/dts/arm/ambiq/ambiq_apollo3_blue.dtsi:401 */
				status = "disabled";           /* in zephyr/dts/arm/ambiq/ambiq_apollo3_blue.dtsi:402 */
				zephyr,pm-device-runtime-auto; /* in zephyr/dts/arm/ambiq/ambiq_apollo3_blue.dtsi:403 */
			};

			/* node '/soc/iom@50009000/i2c' defined in zephyr/dts/arm/ambiq/ambiq_apollo3_blue.dtsi:406 */
			i2c {
				compatible = "ambiq,i2c";      /* in zephyr/dts/arm/ambiq/ambiq_apollo3_blue.dtsi:407 */
				#address-cells = < 0x1 >;      /* in zephyr/dts/arm/ambiq/ambiq_apollo3_blue.dtsi:408 */
				#size-cells = < 0x0 >;         /* in zephyr/dts/arm/ambiq/ambiq_apollo3_blue.dtsi:409 */
				status = "disabled";           /* in zephyr/dts/arm/ambiq/ambiq_apollo3_blue.dtsi:410 */
				zephyr,pm-device-runtime-auto; /* in zephyr/dts/arm/ambiq/ambiq_apollo3_blue.dtsi:411 */
			};
		};

		/* node '/soc/adc@50010000' defined in zephyr/dts/arm/ambiq/ambiq_apollo3_blue.dtsi:415 */
		adc0: adc@50010000 {
			compatible = "ambiq,adc";      /* in zephyr/dts/arm/ambiq/ambiq_apollo3_blue.dtsi:416 */
			reg = < 0x50010000 0x400 >;    /* in zephyr/dts/arm/ambiq/ambiq_apollo3_blue.dtsi:417 */
			interrupts = < 0x12 0x0 >;     /* in zephyr/dts/arm/ambiq/ambiq_apollo3_blue.dtsi:418 */
			interrupt-names = "ADC";       /* in zephyr/dts/arm/ambiq/ambiq_apollo3_blue.dtsi:419 */
			channel-count = < 0xa >;       /* in zephyr/dts/arm/ambiq/ambiq_apollo3_blue.dtsi:420 */
			internal-vref-mv = < 0x5dc >;  /* in zephyr/dts/arm/ambiq/ambiq_apollo3_blue.dtsi:421 */
			#io-channel-cells = < 0x1 >;   /* in zephyr/dts/arm/ambiq/ambiq_apollo3_blue.dtsi:423 */
			pinctrl-0 = < &adc0_default >; /* in zephyr/boards/ambiq/apollo3_evb/apollo3_evb.dts:204 */
			pinctrl-names = "default";     /* in zephyr/boards/ambiq/apollo3_evb/apollo3_evb.dts:205 */
			status = "disabled";           /* in zephyr/boards/ambiq/apollo3_evb/apollo3_evb.dts:206 */
		};

		/* node '/soc/spi@40020000' defined in zephyr/dts/arm/ambiq/ambiq_apollo3_blue.dtsi:426 */
		mspi0: spi@40020000 {
			compatible = "ambiq,mspi";  /* in zephyr/dts/arm/ambiq/ambiq_apollo3_blue.dtsi:427 */
			reg = < 0x40020000 0x400 >; /* in zephyr/dts/arm/ambiq/ambiq_apollo3_blue.dtsi:428 */
			interrupts = < 0x14 0x0 >;  /* in zephyr/dts/arm/ambiq/ambiq_apollo3_blue.dtsi:429 */
			#address-cells = < 0x1 >;   /* in zephyr/dts/arm/ambiq/ambiq_apollo3_blue.dtsi:430 */
			#size-cells = < 0x0 >;      /* in zephyr/dts/arm/ambiq/ambiq_apollo3_blue.dtsi:431 */
			status = "disabled";        /* in zephyr/dts/arm/ambiq/ambiq_apollo3_blue.dtsi:432 */
		};

		/* node '/soc/rtc@40004240' defined in zephyr/dts/arm/ambiq/ambiq_apollo3_blue.dtsi:435 */
		rtc0: rtc@40004240 {
			compatible = "ambiq,rtc";  /* in zephyr/dts/arm/ambiq/ambiq_apollo3_blue.dtsi:436 */
			reg = < 0x40004240 0xd0 >; /* in zephyr/dts/arm/ambiq/ambiq_apollo3_blue.dtsi:437 */
			interrupts = < 0x2 0x0 >;  /* in zephyr/dts/arm/ambiq/ambiq_apollo3_blue.dtsi:438 */
			alarms-count = < 0x1 >;    /* in zephyr/dts/arm/ambiq/ambiq_apollo3_blue.dtsi:439 */
			status = "disabled";       /* in zephyr/boards/ambiq/apollo3_evb/apollo3_evb.dts:199 */
			clock = "XTAL";            /* in zephyr/boards/ambiq/apollo3_evb/apollo3_evb.dts:200 */
		};

		/* node '/soc/spi@5000c000' defined in zephyr/dts/arm/ambiq/ambiq_apollo3_blue.dtsi:443 */
		bleif: spi@5000c000 {
			compatible = "ambiq,spi-bleif"; /* in zephyr/dts/arm/ambiq/ambiq_apollo3_blue.dtsi:444 */
			reg = < 0x5000c000 0x414 >;     /* in zephyr/dts/arm/ambiq/ambiq_apollo3_blue.dtsi:445 */
			interrupts = < 0xc 0x1 >;       /* in zephyr/dts/arm/ambiq/ambiq_apollo3_blue.dtsi:446 */
			#address-cells = < 0x1 >;       /* in zephyr/dts/arm/ambiq/ambiq_apollo3_blue.dtsi:447 */
			#size-cells = < 0x0 >;          /* in zephyr/dts/arm/ambiq/ambiq_apollo3_blue.dtsi:448 */
			pinctrl-0 = < &bleif_default >; /* in zephyr/boards/ambiq/apollo3_evb/apollo3_evb.dts:139 */
			pinctrl-names = "default";      /* in zephyr/boards/ambiq/apollo3_evb/apollo3_evb.dts:140 */
			status = "okay";                /* in zephyr/boards/ambiq/apollo3_evb/apollo3_evb.dts:141 */

			/* node '/soc/spi@5000c000/bt-hci@0' defined in zephyr/dts/arm/ambiq/ambiq_apollo3_blue.dtsi:451 */
			bt_hci_apollo: bt-hci@0 {
				compatible = "ambiq,bt-hci-spi";  /* in zephyr/dts/arm/ambiq/ambiq_apollo3_blue.dtsi:452 */
				spi-max-frequency = < 0x5b8d80 >; /* in zephyr/dts/arm/ambiq/ambiq_apollo3_blue.dtsi:453 */
				reg = < 0x0 >;                    /* in zephyr/dts/arm/ambiq/ambiq_apollo3_blue.dtsi:454 */
			};
		};

		/* node '/soc/pin-controller@40010000' defined in zephyr/dts/arm/ambiq/ambiq_apollo3_blue.dtsi:458 */
		pinctrl: pin-controller@40010000 {
			compatible = "ambiq,apollo3-pinctrl"; /* in zephyr/dts/arm/ambiq/ambiq_apollo3_blue.dtsi:459 */
			reg = < 0x40010000 0x800 >;           /* in zephyr/dts/arm/ambiq/ambiq_apollo3_blue.dtsi:460 */
			#address-cells = < 0x1 >;             /* in zephyr/dts/arm/ambiq/ambiq_apollo3_blue.dtsi:461 */
			#size-cells = < 0x0 >;                /* in zephyr/dts/arm/ambiq/ambiq_apollo3_blue.dtsi:462 */

			/* node '/soc/pin-controller@40010000/gpio@40010000' defined in zephyr/dts/arm/ambiq/ambiq_apollo3_blue.dtsi:464 */
			gpio: gpio@40010000 {
				compatible = "ambiq,gpio";                                            /* in zephyr/dts/arm/ambiq/ambiq_apollo3_blue.dtsi:465 */
				gpio-map-mask = < 0xffffffe0 0xffffffc0 >;                            /* in zephyr/dts/arm/ambiq/ambiq_apollo3_blue.dtsi:466 */
				gpio-map-pass-thru = < 0x1f 0x3f >;                                   /* in zephyr/dts/arm/ambiq/ambiq_apollo3_blue.dtsi:467 */
				gpio-map = < 0x0 0x0 &gpio0_31 0x0 0x0 0x20 0x0 &gpio32_63 0x0 0x0 >; /* in zephyr/dts/arm/ambiq/ambiq_apollo3_blue.dtsi:468 */
				reg = < 0x40010000 >;                                                 /* in zephyr/dts/arm/ambiq/ambiq_apollo3_blue.dtsi:470 */
				#gpio-cells = < 0x2 >;                                                /* in zephyr/dts/arm/ambiq/ambiq_apollo3_blue.dtsi:471 */
				#address-cells = < 0x1 >;                                             /* in zephyr/dts/arm/ambiq/ambiq_apollo3_blue.dtsi:472 */
				#size-cells = < 0x0 >;                                                /* in zephyr/dts/arm/ambiq/ambiq_apollo3_blue.dtsi:473 */
				ranges;                                                               /* in zephyr/dts/arm/ambiq/ambiq_apollo3_blue.dtsi:474 */

				/* node '/soc/pin-controller@40010000/gpio@40010000/gpio0_31@0' defined in zephyr/dts/arm/ambiq/ambiq_apollo3_blue.dtsi:476 */
				gpio0_31: gpio0_31@0 {
					compatible = "ambiq,gpio-bank"; /* in zephyr/dts/arm/ambiq/ambiq_apollo3_blue.dtsi:477 */
					gpio-controller;                /* in zephyr/dts/arm/ambiq/ambiq_apollo3_blue.dtsi:478 */
					#gpio-cells = < 0x2 >;          /* in zephyr/dts/arm/ambiq/ambiq_apollo3_blue.dtsi:479 */
					reg = < 0x0 >;                  /* in zephyr/dts/arm/ambiq/ambiq_apollo3_blue.dtsi:480 */
					interrupts = < 0xd 0x0 >;       /* in zephyr/dts/arm/ambiq/ambiq_apollo3_blue.dtsi:481 */
					status = "okay";                /* in zephyr/boards/ambiq/apollo3_evb/apollo3_evb.dts:210 */
					phandle = < 0x6 >;              /* in zephyr/boards/ambiq/apollo3_evb/apollo3_evb.dts:165 */
				};

				/* node '/soc/pin-controller@40010000/gpio@40010000/gpio32_63@20' defined in zephyr/dts/arm/ambiq/ambiq_apollo3_blue.dtsi:485 */
				gpio32_63: gpio32_63@20 {
					compatible = "ambiq,gpio-bank"; /* in zephyr/dts/arm/ambiq/ambiq_apollo3_blue.dtsi:486 */
					gpio-controller;                /* in zephyr/dts/arm/ambiq/ambiq_apollo3_blue.dtsi:487 */
					#gpio-cells = < 0x2 >;          /* in zephyr/dts/arm/ambiq/ambiq_apollo3_blue.dtsi:488 */
					reg = < 0x20 >;                 /* in zephyr/dts/arm/ambiq/ambiq_apollo3_blue.dtsi:489 */
					interrupts = < 0xd 0x0 >;       /* in zephyr/dts/arm/ambiq/ambiq_apollo3_blue.dtsi:490 */
					ngpios = < 0x12 >;              /* in zephyr/dts/arm/ambiq/ambiq_apollo3_blue.dtsi:492 */
					status = "okay";                /* in zephyr/boards/ambiq/apollo3_evb/apollo3_evb.dts:214 */
					phandle = < 0x8 >;              /* in zephyr/boards/ambiq/apollo3_evb/apollo3_evb.dts:176 */
				};
			};

			/* node '/soc/pin-controller@40010000/uart0_default' defined in zephyr/boards/ambiq/apollo3_evb/apollo3_evb-pinctrl.dtsi:11 */
			uart0_default: uart0_default {
				phandle = < 0x4 >; /* in zephyr/boards/ambiq/apollo3_evb/apollo3_evb.dts:146 */

				/* node '/soc/pin-controller@40010000/uart0_default/group1' defined in zephyr/boards/ambiq/apollo3_evb/apollo3_evb-pinctrl.dtsi:12 */
				group1 {
					pinmux = < 0x160 >; /* in zephyr/boards/ambiq/apollo3_evb/apollo3_evb-pinctrl.dtsi:13 */
				};

				/* node '/soc/pin-controller@40010000/uart0_default/group2' defined in zephyr/boards/ambiq/apollo3_evb/apollo3_evb-pinctrl.dtsi:16 */
				group2 {
					pinmux = < 0x170 >; /* in zephyr/boards/ambiq/apollo3_evb/apollo3_evb-pinctrl.dtsi:17 */
					input-enable;       /* in zephyr/boards/ambiq/apollo3_evb/apollo3_evb-pinctrl.dtsi:18 */
				};
			};

			/* node '/soc/pin-controller@40010000/itm_default' defined in zephyr/boards/ambiq/apollo3_evb/apollo3_evb-pinctrl.dtsi:22 */
			itm_default: itm_default {
				phandle = < 0xd >; /* in zephyr/boards/ambiq/apollo3_evb/apollo3_evb.dts:152 */

				/* node '/soc/pin-controller@40010000/itm_default/group1' defined in zephyr/boards/ambiq/apollo3_evb/apollo3_evb-pinctrl.dtsi:23 */
				group1 {
					pinmux = < 0x292 >; /* in zephyr/boards/ambiq/apollo3_evb/apollo3_evb-pinctrl.dtsi:24 */
				};
			};

			/* node '/soc/pin-controller@40010000/i2c0_default' defined in zephyr/boards/ambiq/apollo3_evb/apollo3_evb-pinctrl.dtsi:28 */
			i2c0_default: i2c0_default {

				/* node '/soc/pin-controller@40010000/i2c0_default/group1' defined in zephyr/boards/ambiq/apollo3_evb/apollo3_evb-pinctrl.dtsi:29 */
				group1 {
					pinmux = < 0x50 >,
					         < 0x60 >;      /* in zephyr/boards/ambiq/apollo3_evb/apollo3_evb-pinctrl.dtsi:30 */
					drive-open-drain;       /* in zephyr/boards/ambiq/apollo3_evb/apollo3_evb-pinctrl.dtsi:31 */
					drive-strength = "0.5"; /* in zephyr/boards/ambiq/apollo3_evb/apollo3_evb-pinctrl.dtsi:32 */
					bias-pull-up;           /* in zephyr/boards/ambiq/apollo3_evb/apollo3_evb-pinctrl.dtsi:33 */
				};
			};

			/* node '/soc/pin-controller@40010000/i2c1_default' defined in zephyr/boards/ambiq/apollo3_evb/apollo3_evb-pinctrl.dtsi:37 */
			i2c1_default: i2c1_default {

				/* node '/soc/pin-controller@40010000/i2c1_default/group1' defined in zephyr/boards/ambiq/apollo3_evb/apollo3_evb-pinctrl.dtsi:38 */
				group1 {
					pinmux = < 0x80 >,
					         < 0x90 >;      /* in zephyr/boards/ambiq/apollo3_evb/apollo3_evb-pinctrl.dtsi:39 */
					drive-open-drain;       /* in zephyr/boards/ambiq/apollo3_evb/apollo3_evb-pinctrl.dtsi:40 */
					drive-strength = "0.5"; /* in zephyr/boards/ambiq/apollo3_evb/apollo3_evb-pinctrl.dtsi:41 */
					bias-pull-up;           /* in zephyr/boards/ambiq/apollo3_evb/apollo3_evb-pinctrl.dtsi:42 */
				};
			};

			/* node '/soc/pin-controller@40010000/i2c2_default' defined in zephyr/boards/ambiq/apollo3_evb/apollo3_evb-pinctrl.dtsi:46 */
			i2c2_default: i2c2_default {

				/* node '/soc/pin-controller@40010000/i2c2_default/group1' defined in zephyr/boards/ambiq/apollo3_evb/apollo3_evb-pinctrl.dtsi:47 */
				group1 {
					pinmux = < 0x1b4 >,
					         < 0x194 >;     /* in zephyr/boards/ambiq/apollo3_evb/apollo3_evb-pinctrl.dtsi:48 */
					drive-open-drain;       /* in zephyr/boards/ambiq/apollo3_evb/apollo3_evb-pinctrl.dtsi:49 */
					drive-strength = "0.5"; /* in zephyr/boards/ambiq/apollo3_evb/apollo3_evb-pinctrl.dtsi:50 */
					bias-pull-up;           /* in zephyr/boards/ambiq/apollo3_evb/apollo3_evb-pinctrl.dtsi:51 */
				};
			};

			/* node '/soc/pin-controller@40010000/i2c3_default' defined in zephyr/boards/ambiq/apollo3_evb/apollo3_evb-pinctrl.dtsi:55 */
			i2c3_default: i2c3_default {
				phandle = < 0x7 >; /* in zephyr/boards/ambiq/apollo3_evb/apollo3_evb.dts:173 */

				/* node '/soc/pin-controller@40010000/i2c3_default/group1' defined in zephyr/boards/ambiq/apollo3_evb/apollo3_evb-pinctrl.dtsi:56 */
				group1 {
					pinmux = < 0x2a4 >,
					         < 0x2b4 >;     /* in zephyr/boards/ambiq/apollo3_evb/apollo3_evb-pinctrl.dtsi:57 */
					drive-open-drain;       /* in zephyr/boards/ambiq/apollo3_evb/apollo3_evb-pinctrl.dtsi:58 */
					drive-strength = "0.5"; /* in zephyr/boards/ambiq/apollo3_evb/apollo3_evb-pinctrl.dtsi:59 */
					bias-pull-up;           /* in zephyr/boards/ambiq/apollo3_evb/apollo3_evb-pinctrl.dtsi:60 */
				};
			};

			/* node '/soc/pin-controller@40010000/i2c4_default' defined in zephyr/boards/ambiq/apollo3_evb/apollo3_evb-pinctrl.dtsi:64 */
			i2c4_default: i2c4_default {

				/* node '/soc/pin-controller@40010000/i2c4_default/group1' defined in zephyr/boards/ambiq/apollo3_evb/apollo3_evb-pinctrl.dtsi:65 */
				group1 {
					pinmux = < 0x274 >,
					         < 0x284 >;     /* in zephyr/boards/ambiq/apollo3_evb/apollo3_evb-pinctrl.dtsi:66 */
					drive-open-drain;       /* in zephyr/boards/ambiq/apollo3_evb/apollo3_evb-pinctrl.dtsi:67 */
					drive-strength = "0.5"; /* in zephyr/boards/ambiq/apollo3_evb/apollo3_evb-pinctrl.dtsi:68 */
					bias-pull-up;           /* in zephyr/boards/ambiq/apollo3_evb/apollo3_evb-pinctrl.dtsi:69 */
				};
			};

			/* node '/soc/pin-controller@40010000/i2c5_default' defined in zephyr/boards/ambiq/apollo3_evb/apollo3_evb-pinctrl.dtsi:73 */
			i2c5_default: i2c5_default {

				/* node '/soc/pin-controller@40010000/i2c5_default/group1' defined in zephyr/boards/ambiq/apollo3_evb/apollo3_evb-pinctrl.dtsi:74 */
				group1 {
					pinmux = < 0x304 >,
					         < 0x314 >;     /* in zephyr/boards/ambiq/apollo3_evb/apollo3_evb-pinctrl.dtsi:75 */
					drive-open-drain;       /* in zephyr/boards/ambiq/apollo3_evb/apollo3_evb-pinctrl.dtsi:76 */
					drive-strength = "0.5"; /* in zephyr/boards/ambiq/apollo3_evb/apollo3_evb-pinctrl.dtsi:77 */
					bias-pull-up;           /* in zephyr/boards/ambiq/apollo3_evb/apollo3_evb-pinctrl.dtsi:78 */
				};
			};

			/* node '/soc/pin-controller@40010000/spid0_default' defined in zephyr/boards/ambiq/apollo3_evb/apollo3_evb-pinctrl.dtsi:82 */
			spid0_default: spid0_default {

				/* node '/soc/pin-controller@40010000/spid0_default/group1' defined in zephyr/boards/ambiq/apollo3_evb/apollo3_evb-pinctrl.dtsi:83 */
				group1 {
					pinmux = < 0x1 >,
					         < 0x21 >,
					         < 0x11 >,
					         < 0x31 >; /* in zephyr/boards/ambiq/apollo3_evb/apollo3_evb-pinctrl.dtsi:84 */
				};
			};

			/* node '/soc/pin-controller@40010000/spi0_default' defined in zephyr/boards/ambiq/apollo3_evb/apollo3_evb-pinctrl.dtsi:88 */
			spi0_default: spi0_default {
				phandle = < 0x5 >; /* in zephyr/boards/ambiq/apollo3_evb/apollo3_evb.dts:163 */

				/* node '/soc/pin-controller@40010000/spi0_default/group1' defined in zephyr/boards/ambiq/apollo3_evb/apollo3_evb-pinctrl.dtsi:89 */
				group1 {
					pinmux = < 0x51 >,
					         < 0x61 >,
					         < 0x71 >; /* in zephyr/boards/ambiq/apollo3_evb/apollo3_evb-pinctrl.dtsi:90 */
				};
			};

			/* node '/soc/pin-controller@40010000/spi1_default' defined in zephyr/boards/ambiq/apollo3_evb/apollo3_evb-pinctrl.dtsi:94 */
			spi1_default: spi1_default {

				/* node '/soc/pin-controller@40010000/spi1_default/group1' defined in zephyr/boards/ambiq/apollo3_evb/apollo3_evb-pinctrl.dtsi:95 */
				group1 {
					pinmux = < 0x81 >,
					         < 0x91 >,
					         < 0xa1 >; /* in zephyr/boards/ambiq/apollo3_evb/apollo3_evb-pinctrl.dtsi:96 */
				};
			};

			/* node '/soc/pin-controller@40010000/spi2_default' defined in zephyr/boards/ambiq/apollo3_evb/apollo3_evb-pinctrl.dtsi:100 */
			spi2_default: spi2_default {

				/* node '/soc/pin-controller@40010000/spi2_default/group1' defined in zephyr/boards/ambiq/apollo3_evb/apollo3_evb-pinctrl.dtsi:101 */
				group1 {
					pinmux = < 0x1b5 >,
					         < 0x195 >,
					         < 0x1c5 >; /* in zephyr/boards/ambiq/apollo3_evb/apollo3_evb-pinctrl.dtsi:102 */
				};
			};

			/* node '/soc/pin-controller@40010000/spi3_default' defined in zephyr/boards/ambiq/apollo3_evb/apollo3_evb-pinctrl.dtsi:106 */
			spi3_default: spi3_default {

				/* node '/soc/pin-controller@40010000/spi3_default/group1' defined in zephyr/boards/ambiq/apollo3_evb/apollo3_evb-pinctrl.dtsi:107 */
				group1 {
					pinmux = < 0x2a5 >,
					         < 0x2b5 >,
					         < 0x265 >; /* in zephyr/boards/ambiq/apollo3_evb/apollo3_evb-pinctrl.dtsi:108 */
				};
			};

			/* node '/soc/pin-controller@40010000/spi4_default' defined in zephyr/boards/ambiq/apollo3_evb/apollo3_evb-pinctrl.dtsi:112 */
			spi4_default: spi4_default {

				/* node '/soc/pin-controller@40010000/spi4_default/group1' defined in zephyr/boards/ambiq/apollo3_evb/apollo3_evb-pinctrl.dtsi:113 */
				group1 {
					pinmux = < 0x275 >,
					         < 0x285 >,
					         < 0x2c5 >; /* in zephyr/boards/ambiq/apollo3_evb/apollo3_evb-pinctrl.dtsi:114 */
				};
			};

			/* node '/soc/pin-controller@40010000/spi5_default' defined in zephyr/boards/ambiq/apollo3_evb/apollo3_evb-pinctrl.dtsi:118 */
			spi5_default: spi5_default {

				/* node '/soc/pin-controller@40010000/spi5_default/group1' defined in zephyr/boards/ambiq/apollo3_evb/apollo3_evb-pinctrl.dtsi:119 */
				group1 {
					pinmux = < 0x305 >,
					         < 0x315 >,
					         < 0x2f5 >; /* in zephyr/boards/ambiq/apollo3_evb/apollo3_evb-pinctrl.dtsi:120 */
				};
			};

			/* node '/soc/pin-controller@40010000/adc0_default' defined in zephyr/boards/ambiq/apollo3_evb/apollo3_evb-pinctrl.dtsi:124 */
			adc0_default: adc0_default {
				phandle = < 0x9 >; /* in zephyr/boards/ambiq/apollo3_evb/apollo3_evb.dts:204 */

				/* node '/soc/pin-controller@40010000/adc0_default/group1' defined in zephyr/boards/ambiq/apollo3_evb/apollo3_evb-pinctrl.dtsi:125 */
				group1 {
					pinmux = < 0x200 >,
					         < 0x230 >;     /* in zephyr/boards/ambiq/apollo3_evb/apollo3_evb-pinctrl.dtsi:126 */
					drive-strength = "0.1"; /* in zephyr/boards/ambiq/apollo3_evb/apollo3_evb-pinctrl.dtsi:127 */
				};
			};

			/* node '/soc/pin-controller@40010000/mspi0_default' defined in zephyr/boards/ambiq/apollo3_evb/apollo3_evb-pinctrl.dtsi:131 */
			mspi0_default: mspi0_default {

				/* node '/soc/pin-controller@40010000/mspi0_default/group1' defined in zephyr/boards/ambiq/apollo3_evb/apollo3_evb-pinctrl.dtsi:132 */
				group1 {
					pinmux = < 0x166 >,
					         < 0x1a5 >,
					         < 0x47 >,
					         < 0x176 >,
					         < 0x182 >; /* in zephyr/boards/ambiq/apollo3_evb/apollo3_evb-pinctrl.dtsi:133 */
				};

				/* node '/soc/pin-controller@40010000/mspi0_default/group2' defined in zephyr/boards/ambiq/apollo3_evb/apollo3_evb-pinctrl.dtsi:140 */
				group2 {
					pinmux = < 0x131 >;      /* in zephyr/boards/ambiq/apollo3_evb/apollo3_evb-pinctrl.dtsi:141 */
					drive-push-pull;         /* in zephyr/boards/ambiq/apollo3_evb/apollo3_evb-pinctrl.dtsi:142 */
					drive-strength = "0.5";  /* in zephyr/boards/ambiq/apollo3_evb/apollo3_evb-pinctrl.dtsi:143 */
					ambiq,nce-src = < 0x0 >; /* in zephyr/boards/ambiq/apollo3_evb/apollo3_evb-pinctrl.dtsi:144 */
					ambiq,iom-num = < 0x6 >; /* in zephyr/boards/ambiq/apollo3_evb/apollo3_evb-pinctrl.dtsi:145 */
				};
			};

			/* node '/soc/pin-controller@40010000/bleif_default' defined in zephyr/boards/ambiq/apollo3_evb/apollo3_evb-pinctrl.dtsi:149 */
			bleif_default: bleif_default {
				phandle = < 0xa >; /* in zephyr/boards/ambiq/apollo3_evb/apollo3_evb.dts:139 */

				/* node '/soc/pin-controller@40010000/bleif_default/group1' defined in zephyr/boards/ambiq/apollo3_evb/apollo3_evb-pinctrl.dtsi:150 */
				group1 {
					pinmux = < 0x1e6 >,
					         < 0x1f6 >,
					         < 0x206 >,
					         < 0x214 >,
					         < 0x237 >,
					         < 0x291 >; /* in zephyr/boards/ambiq/apollo3_evb/apollo3_evb-pinctrl.dtsi:151 */
				};
			};

			/* node '/soc/pin-controller@40010000/pwm2_default' defined in zephyr/boards/ambiq/apollo3_evb/apollo3_evb-pinctrl.dtsi:160 */
			pwm2_default: pwm2_default {
				phandle = < 0x2 >; /* in zephyr/boards/ambiq/apollo3_evb/apollo3_evb.dts:192 */

				/* node '/soc/pin-controller@40010000/pwm2_default/group1' defined in zephyr/boards/ambiq/apollo3_evb/apollo3_evb-pinctrl.dtsi:161 */
				group1 {
					pinmux = < 0x1e3 >; /* in zephyr/boards/ambiq/apollo3_evb/apollo3_evb-pinctrl.dtsi:162 */
				};
			};
		};

		/* node '/soc/watchdog@40024000' defined in zephyr/dts/arm/ambiq/ambiq_apollo3_blue.dtsi:497 */
		wdt0: watchdog@40024000 {
			compatible = "ambiq,watchdog"; /* in zephyr/dts/arm/ambiq/ambiq_apollo3_blue.dtsi:498 */
			reg = < 0x40024000 0x400 >;    /* in zephyr/dts/arm/ambiq/ambiq_apollo3_blue.dtsi:499 */
			interrupts = < 0x1 0x0 >;      /* in zephyr/dts/arm/ambiq/ambiq_apollo3_blue.dtsi:500 */
			clock-frequency = < 0x10 >;    /* in zephyr/dts/arm/ambiq/ambiq_apollo3_blue.dtsi:501 */
			status = "okay";               /* in zephyr/boards/ambiq/apollo3_evb/apollo3_evb.dts:158 */
		};
	};

	/* node '/clocks' defined in zephyr/dts/arm/ambiq/ambiq_apollo3_blue.dtsi:12 */
	clocks {

		/* node '/clocks/apb-pclk' defined in zephyr/dts/arm/ambiq/ambiq_apollo3_blue.dtsi:13 */
		uartclk: apb-pclk {
			compatible = "fixed-clock";      /* in zephyr/dts/arm/ambiq/ambiq_apollo3_blue.dtsi:14 */
			clock-frequency = < 0x16e3600 >; /* in zephyr/dts/arm/ambiq/ambiq_apollo3_blue.dtsi:15 */
			#clock-cells = < 0x0 >;          /* in zephyr/dts/arm/ambiq/ambiq_apollo3_blue.dtsi:16 */
			phandle = < 0x3 >;               /* in zephyr/dts/arm/ambiq/ambiq_apollo3_blue.dtsi:259 */
		};
	};

	/* node '/cpus' defined in zephyr/dts/arm/ambiq/ambiq_apollo3_blue.dtsi:20 */
	cpus {
		#address-cells = < 0x1 >; /* in zephyr/dts/arm/ambiq/ambiq_apollo3_blue.dtsi:21 */
		#size-cells = < 0x0 >;    /* in zephyr/dts/arm/ambiq/ambiq_apollo3_blue.dtsi:22 */

		/* node '/cpus/cpu@0' defined in zephyr/dts/arm/ambiq/ambiq_apollo3_blue.dtsi:24 */
		cpu0: cpu@0 {
			compatible = "arm,cortex-m4f";                /* in zephyr/dts/arm/ambiq/ambiq_apollo3_blue.dtsi:25 */
			reg = < 0x0 >;                                /* in zephyr/dts/arm/ambiq/ambiq_apollo3_blue.dtsi:26 */
			cpu-power-states = < &idle &suspend_to_ram >; /* in zephyr/dts/arm/ambiq/ambiq_apollo3_blue.dtsi:27 */
			#address-cells = < 0x1 >;                     /* in zephyr/dts/arm/ambiq/ambiq_apollo3_blue.dtsi:28 */
			#size-cells = < 0x1 >;                        /* in zephyr/dts/arm/ambiq/ambiq_apollo3_blue.dtsi:29 */

			/* node '/cpus/cpu@0/itm@e0000000' defined in zephyr/dts/arm/ambiq/ambiq_apollo3_blue.dtsi:31 */
			itm: itm@e0000000 {
				compatible = "arm,armv7m-itm";    /* in zephyr/dts/arm/ambiq/ambiq_apollo3_blue.dtsi:32 */
				reg = < 0xe0000000 0x1000 >;      /* in zephyr/dts/arm/ambiq/ambiq_apollo3_blue.dtsi:33 */
				swo-ref-frequency = < 0x5b8d80 >; /* in zephyr/dts/arm/ambiq/ambiq_apollo3_blue.dtsi:34 */
				pinctrl-0 = < &itm_default >;     /* in zephyr/boards/ambiq/apollo3_evb/apollo3_evb.dts:152 */
				pinctrl-names = "default";        /* in zephyr/boards/ambiq/apollo3_evb/apollo3_evb.dts:153 */
				status = "okay";                  /* in zephyr/boards/ambiq/apollo3_evb/apollo3_evb.dts:154 */
			};
		};

		/* node '/cpus/power-states' defined in zephyr/dts/arm/ambiq/ambiq_apollo3_blue.dtsi:38 */
		power-states {

			/* node '/cpus/power-states/idle' defined in zephyr/dts/arm/ambiq/ambiq_apollo3_blue.dtsi:39 */
			idle: idle {
				compatible = "zephyr,power-state";    /* in zephyr/dts/arm/ambiq/ambiq_apollo3_blue.dtsi:40 */
				power-state-name = "suspend-to-idle"; /* in zephyr/dts/arm/ambiq/ambiq_apollo3_blue.dtsi:41 */
				min-residency-us = < 0x64 >;          /* in zephyr/dts/arm/ambiq/ambiq_apollo3_blue.dtsi:46 */
				exit-latency-us = < 0x5 >;            /* in zephyr/dts/arm/ambiq/ambiq_apollo3_blue.dtsi:47 */
				phandle = < 0xb >;                    /* in zephyr/dts/arm/ambiq/ambiq_apollo3_blue.dtsi:27 */
			};

			/* node '/cpus/power-states/suspend_to_ram' defined in zephyr/dts/arm/ambiq/ambiq_apollo3_blue.dtsi:50 */
			suspend_to_ram: suspend_to_ram {
				compatible = "zephyr,power-state";   /* in zephyr/dts/arm/ambiq/ambiq_apollo3_blue.dtsi:51 */
				power-state-name = "suspend-to-ram"; /* in zephyr/dts/arm/ambiq/ambiq_apollo3_blue.dtsi:52 */
				min-residency-us = < 0x7d0 >;        /* in zephyr/dts/arm/ambiq/ambiq_apollo3_blue.dtsi:58 */
				exit-latency-us = < 0x7d >;          /* in zephyr/dts/arm/ambiq/ambiq_apollo3_blue.dtsi:59 */
				phandle = < 0xc >;                   /* in zephyr/dts/arm/ambiq/ambiq_apollo3_blue.dtsi:27 */
			};
		};
	};

	/* node '/tcm@10000000' defined in zephyr/dts/arm/ambiq/ambiq_apollo3_blue.dtsi:65 */
	tcm: tcm@10000000 {
		compatible = "zephyr,memory-region"; /* in zephyr/dts/arm/ambiq/ambiq_apollo3_blue.dtsi:66 */
		reg = < 0x10000000 0x10000 >;        /* in zephyr/dts/arm/ambiq/ambiq_apollo3_blue.dtsi:67 */
		zephyr,memory-region = "ITCM";       /* in zephyr/dts/arm/ambiq/ambiq_apollo3_blue.dtsi:68 */
	};

	/* node '/memory@10010000' defined in zephyr/dts/arm/ambiq/ambiq_apollo3_blue.dtsi:72 */
	sram0: memory@10010000 {
		compatible = "mmio-sram";     /* in zephyr/dts/arm/ambiq/ambiq_apollo3_blue.dtsi:73 */
		reg = < 0x10010000 0x50000 >; /* in zephyr/dts/arm/ambiq/ambiq_apollo3_blue.dtsi:74 */
	};

	/* node '/connector' defined in zephyr/boards/ambiq/apollo3_evb/apollo3_evb_connector.dtsi:8 */
	ambiq_header: connector {
		compatible = "ambiq-header";                 /* in zephyr/boards/ambiq/apollo3_evb/apollo3_evb_connector.dtsi:9 */
		#gpio-cells = < 0x2 >;                       /* in zephyr/boards/ambiq/apollo3_evb/apollo3_evb_connector.dtsi:10 */
		gpio-map-mask = < 0xffffffff 0xffffff80 >;   /* in zephyr/boards/ambiq/apollo3_evb/apollo3_evb_connector.dtsi:11 */
		gpio-map-pass-thru = < 0x0 0x7f >;           /* in zephyr/boards/ambiq/apollo3_evb/apollo3_evb_connector.dtsi:12 */
		gpio-map = < 0x0 0x0 &gpio0_31 0x0 0x0 >,
		           < 0x1 0x0 &gpio0_31 0x1 0x0 >,
		           < 0x2 0x0 &gpio0_31 0x2 0x0 >,
		           < 0x3 0x0 &gpio0_31 0x3 0x0 >,
		           < 0x4 0x0 &gpio0_31 0x4 0x0 >,
		           < 0x5 0x0 &gpio0_31 0x5 0x0 >,
		           < 0x6 0x0 &gpio0_31 0x6 0x0 >,
		           < 0x7 0x0 &gpio0_31 0x7 0x0 >,
		           < 0x8 0x0 &gpio0_31 0x8 0x0 >,
		           < 0x9 0x0 &gpio0_31 0x9 0x0 >,
		           < 0xa 0x0 &gpio0_31 0xa 0x0 >,
		           < 0xb 0x0 &gpio0_31 0xb 0x0 >,
		           < 0xc 0x0 &gpio0_31 0xc 0x0 >,
		           < 0xd 0x0 &gpio0_31 0xd 0x0 >,
		           < 0xe 0x0 &gpio0_31 0xe 0x0 >,
		           < 0xf 0x0 &gpio0_31 0xf 0x0 >,
		           < 0x10 0x0 &gpio0_31 0x10 0x0 >,
		           < 0x11 0x0 &gpio0_31 0x11 0x0 >,
		           < 0x12 0x0 &gpio0_31 0x12 0x0 >,
		           < 0x13 0x0 &gpio0_31 0x13 0x0 >,
		           < 0x14 0x0 &gpio0_31 0x14 0x0 >,
		           < 0x15 0x0 &gpio0_31 0x15 0x0 >,
		           < 0x16 0x0 &gpio0_31 0x16 0x0 >,
		           < 0x17 0x0 &gpio0_31 0x17 0x0 >,
		           < 0x18 0x0 &gpio0_31 0x18 0x0 >,
		           < 0x19 0x0 &gpio0_31 0x19 0x0 >,
		           < 0x1a 0x0 &gpio0_31 0x1a 0x0 >,
		           < 0x1b 0x0 &gpio0_31 0x1b 0x0 >,
		           < 0x1c 0x0 &gpio0_31 0x1c 0x0 >,
		           < 0x1d 0x0 &gpio0_31 0x1d 0x0 >,
		           < 0x1e 0x0 &gpio0_31 0x1e 0x0 >,
		           < 0x1f 0x0 &gpio0_31 0x1f 0x0 >,
		           < 0x20 0x0 &gpio32_63 0x0 0x0 >,
		           < 0x21 0x0 &gpio32_63 0x1 0x0 >,
		           < 0x22 0x0 &gpio32_63 0x2 0x0 >,
		           < 0x23 0x0 &gpio32_63 0x3 0x0 >,
		           < 0x24 0x0 &gpio32_63 0x4 0x0 >,
		           < 0x25 0x0 &gpio32_63 0x5 0x0 >,
		           < 0x26 0x0 &gpio32_63 0x6 0x0 >,
		           < 0x27 0x0 &gpio32_63 0x7 0x0 >,
		           < 0x28 0x0 &gpio32_63 0x8 0x0 >,
		           < 0x29 0x0 &gpio32_63 0x9 0x0 >,
		           < 0x2a 0x0 &gpio32_63 0xa 0x0 >,
		           < 0x2b 0x0 &gpio32_63 0xb 0x0 >,
		           < 0x2c 0x0 &gpio32_63 0xc 0x0 >,
		           < 0x2d 0x0 &gpio32_63 0xd 0x0 >,
		           < 0x2e 0x0 &gpio32_63 0xe 0x0 >,
		           < 0x2f 0x0 &gpio32_63 0xf 0x0 >,
		           < 0x30 0x0 &gpio32_63 0x10 0x0 >,
		           < 0x31 0x0 &gpio32_63 0x11 0x0 >; /* in zephyr/boards/ambiq/apollo3_evb/apollo3_evb_connector.dtsi:13 */
	};

	/* node '/leds' defined in zephyr/boards/ambiq/apollo3_evb/apollo3_evb.dts:35 */
	leds {
		compatible = "gpio-leds"; /* in zephyr/boards/ambiq/apollo3_evb/apollo3_evb.dts:36 */

		/* node '/leds/led_0' defined in zephyr/boards/ambiq/apollo3_evb/apollo3_evb.dts:38 */
		led0: led_0 {
			gpios = < &gpio0_31 0xa 0x1 >; /* in zephyr/boards/ambiq/apollo3_evb/apollo3_evb.dts:39 */
			label = "LED 0";               /* in zephyr/boards/ambiq/apollo3_evb/apollo3_evb.dts:40 */
		};

		/* node '/leds/led_1' defined in zephyr/boards/ambiq/apollo3_evb/apollo3_evb.dts:43 */
		led1: led_1 {
			gpios = < &gpio0_31 0x1e 0x1 >; /* in zephyr/boards/ambiq/apollo3_evb/apollo3_evb.dts:44 */
			label = "LED 1";                /* in zephyr/boards/ambiq/apollo3_evb/apollo3_evb.dts:45 */
		};

		/* node '/leds/led_2' defined in zephyr/boards/ambiq/apollo3_evb/apollo3_evb.dts:48 */
		led2: led_2 {
			gpios = < &gpio0_31 0xf 0x1 >; /* in zephyr/boards/ambiq/apollo3_evb/apollo3_evb.dts:49 */
			label = "LED 2";               /* in zephyr/boards/ambiq/apollo3_evb/apollo3_evb.dts:50 */
		};

		/* node '/leds/led_3' defined in zephyr/boards/ambiq/apollo3_evb/apollo3_evb.dts:53 */
		led3: led_3 {
			gpios = < &gpio0_31 0xe 0x1 >; /* in zephyr/boards/ambiq/apollo3_evb/apollo3_evb.dts:54 */
			label = "LED 3";               /* in zephyr/boards/ambiq/apollo3_evb/apollo3_evb.dts:55 */
		};

		/* node '/leds/led_4' defined in zephyr/boards/ambiq/apollo3_evb/apollo3_evb.dts:58 */
		led4: led_4 {
			gpios = < &gpio0_31 0x11 0x1 >; /* in zephyr/boards/ambiq/apollo3_evb/apollo3_evb.dts:59 */
			label = "LED 4";                /* in zephyr/boards/ambiq/apollo3_evb/apollo3_evb.dts:60 */
		};
	};

	/* node '/buttons' defined in zephyr/boards/ambiq/apollo3_evb/apollo3_evb.dts:64 */
	buttons {
		compatible = "gpio-keys"; /* in zephyr/boards/ambiq/apollo3_evb/apollo3_evb.dts:65 */

		/* node '/buttons/button_0' defined in zephyr/boards/ambiq/apollo3_evb/apollo3_evb.dts:67 */
		button0: button_0 {
			gpios = < &gpio0_31 0x10 0x1 >; /* in zephyr/boards/ambiq/apollo3_evb/apollo3_evb.dts:68 */
			label = "BTN0";                 /* in zephyr/boards/ambiq/apollo3_evb/apollo3_evb.dts:69 */
			zephyr,code = < 0xb >;          /* in zephyr/boards/ambiq/apollo3_evb/apollo3_evb.dts:70 */
		};

		/* node '/buttons/button_1' defined in zephyr/boards/ambiq/apollo3_evb/apollo3_evb.dts:73 */
		button1: button_1 {
			gpios = < &gpio0_31 0x12 0x1 >; /* in zephyr/boards/ambiq/apollo3_evb/apollo3_evb.dts:74 */
			label = "BTN1";                 /* in zephyr/boards/ambiq/apollo3_evb/apollo3_evb.dts:75 */
			zephyr,code = < 0x2 >;          /* in zephyr/boards/ambiq/apollo3_evb/apollo3_evb.dts:76 */
		};

		/* node '/buttons/button_2' defined in zephyr/boards/ambiq/apollo3_evb/apollo3_evb.dts:79 */
		button2: button_2 {
			gpios = < &gpio0_31 0x13 0x1 >; /* in zephyr/boards/ambiq/apollo3_evb/apollo3_evb.dts:80 */
			label = "BTN2";                 /* in zephyr/boards/ambiq/apollo3_evb/apollo3_evb.dts:81 */
			zephyr,code = < 0x3 >;          /* in zephyr/boards/ambiq/apollo3_evb/apollo3_evb.dts:82 */
		};
	};

	/* node '/pwmleds' defined in zephyr/boards/ambiq/apollo3_evb/apollo3_evb.dts:86 */
	pwmleds: pwmleds {
		compatible = "pwm-leds"; /* in zephyr/boards/ambiq/apollo3_evb/apollo3_evb.dts:87 */
		status = "disabled";     /* in zephyr/boards/ambiq/apollo3_evb/apollo3_evb.dts:88 */

		/* node '/pwmleds/pwm_led_0' defined in zephyr/boards/ambiq/apollo3_evb/apollo3_evb.dts:90 */
		pwm_led0: pwm_led_0 {
			pwms = < &pwm2 0x0 0x1312d00 0x0 >; /* in zephyr/boards/ambiq/apollo3_evb/apollo3_evb.dts:91 */
			label = "PWM_LED";                  /* in zephyr/boards/ambiq/apollo3_evb/apollo3_evb.dts:92 */
		};
	};
};
